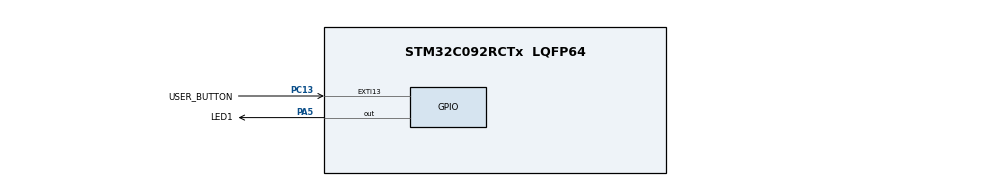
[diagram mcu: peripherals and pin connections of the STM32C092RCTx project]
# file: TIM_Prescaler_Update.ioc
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Mcu.Family=STM32C0
Mcu.Name=STM32C092RCTx
Mcu.Package=LQFP64
NVIC.EXTI4_15_IRQn=true\:0\:0\:false\:false\:true\:true\:true\:true
NVIC.TIM1_BRK_UP_TRG_COM_IRQn=true\:0\:0\:false\:false\:true\:true\:true\:true
PA5.GPIO_Label=LED1
PA5.GPIO_Speed=GPIO_SPEED_FREQ_HIGH
PA5.Signal=GPIO_Output
PC13.GPIO_Label=USER_BUTTON
PC13.GPIO_PuPd=GPIO_PULLUP
PC13.Signal=GPXTI13
ProjectManager.HeapSize=0x200
ProjectManager.StackSize=0x400
ProjectManager.TargetToolchain=EWARM V9.20
RCC.ADCFreq_Value=48000000
RCC.AHBFreq_Value=48000000
RCC.CortexFreq_Value=48000000
RCC.EXTERNAL_CLOCK_VALUE=12288000
RCC.HCLKFreq_Value=48000000
RCC.HSE_VALUE=8000000
RCC.HSISYSCLKDivider=RCC_HSI_DIV1
RCC.HSI_VALUE=48000000
RCC.LSE_VALUE=32768
RCC.SYSCLKFreq_VALUE=48000000
TIM1.Period=999
TIM1.Prescaler=aPrescaler[0]
VP_TIM1_VS_ClockSourceINT.Mode=Internal
board=custom

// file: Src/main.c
/* USER CODE BEGIN Header */
/**
  ******************************************************************************
  * @file           : main.c
  * @brief          : Main program body
  ******************************************************************************
  * @attention
  *
  * Copyright (c) 2024 STMicroelectronics.
  * All rights reserved.
  *
  * This software is licensed under terms that can be found in the LICENSE file
  * in the root directory of this software component.
  * If no LICENSE file comes with this software, it is provided AS-IS.
  *
  ******************************************************************************
  */
/* USER CODE END Header */
#include "main.h"

/* USER CODE BEGIN PD */
#define TAB_SIZE 3
/* USER CODE END PD */

/* USER CODE BEGIN PV */
/* Prescaler value table for 4kHz, 2kHz and 1kHz */
static uint32_t aPrescaler[TAB_SIZE] = {12000-1, 24000-1, 48000-1};

/* Actual autoreload value multiplication factor */
static uint32_t prescaler_index = 1;
/* USER CODE END PV */

void SystemClock_Config(void);
static void MX_GPIO_Init(void);
static void MX_TIM1_Init(void);

int main(void)
{

  /* MCU Configuration--------------------------------------------------------*/

  /* Reset of all peripherals, Initializes the Flash interface and the Systick. */
  LL_APB2_GRP1_EnableClock(LL_APB2_GRP1_PERIPH_SYSCFG);
  LL_APB1_GRP1_EnableClock(LL_APB1_GRP1_PERIPH_PWR);

  /* SysTick_IRQn interrupt configuration */
  NVIC_SetPriority(SysTick_IRQn, 3);

  /* Configure the system clock */
  SystemClock_Config();

  /* Initialize all configured peripherals */
  MX_GPIO_Init();
  MX_TIM1_Init();
  /* USER CODE BEGIN 2 */

  /* Enable Update interrupt */
  LL_TIM_EnableIT_UPDATE(TIM1);

  /* Enable counter */
  LL_TIM_EnableCounter(TIM1);

  /* USER CODE END 2 */

  /* Infinite loop */
  while (1)
  {

  }
}

void SystemClock_Config(void)
{

  LL_FLASH_SetLatency(LL_FLASH_LATENCY_1);

  /* HSI configuration and activation */
  LL_RCC_HSI_Enable();
  while(LL_RCC_HSI_IsReady() != 1)
  {
  }

  LL_RCC_HSI_SetCalibTrimming(64);
  LL_RCC_SetHSIDiv(LL_RCC_HSI_DIV_1);
  /* Set AHB prescaler*/
  LL_RCC_SetAHBPrescaler(LL_RCC_HCLK_DIV_1);

  LL_RCC_SetSYSDivider(LL_RCC_SYSCLK_DIV_1);
  /* Sysclk activation on the HSI */
  LL_RCC_SetSysClkSource(LL_RCC_SYS_CLKSOURCE_HSI);
  while(LL_RCC_GetSysClkSource() != LL_RCC_SYS_CLKSOURCE_STATUS_HSI)
  {
  }

  /* Set APB1 prescaler*/
  LL_RCC_SetAPB1Prescaler(LL_RCC_APB1_DIV_1);
  LL_Init1msTick(48000000);
  /* Update CMSIS variable (which can be updated also through SystemCoreClockUpdate function) */
  LL_SetSystemCoreClock(48000000);
}

static void MX_TIM1_Init(void)
{

  LL_TIM_InitTypeDef TIM_InitStruct = {0};

  /* Peripheral clock enable */
  LL_APB2_GRP1_EnableClock(LL_APB2_GRP1_PERIPH_TIM1);

  /* TIM1 interrupt Init */
  NVIC_SetPriority(TIM1_BRK_UP_TRG_COM_IRQn, 0);
  NVIC_EnableIRQ(TIM1_BRK_UP_TRG_COM_IRQn);

  /* USER CODE BEGIN TIM1_Init 1 */

  /* Disable update interrupt with update event generation (TIM1_EGR.UG).
     Avoid update interrupt with LL_TIM_Init where an update event is
     generated to load the values in the active registers. */
  LL_TIM_SetUpdateSource(TIM1, LL_TIM_UPDATESOURCE_COUNTER);

  /* USER CODE END TIM1_Init 1 */
  TIM_InitStruct.Prescaler = aPrescaler[0];
  TIM_InitStruct.CounterMode = LL_TIM_COUNTERMODE_UP;
  TIM_InitStruct.Autoreload = 999;
  TIM_InitStruct.ClockDivision = LL_TIM_CLOCKDIVISION_DIV1;
  TIM_InitStruct.RepetitionCounter = 0;
  LL_TIM_Init(TIM1, &TIM_InitStruct);
  LL_TIM_DisableARRPreload(TIM1);
  LL_TIM_SetClockSource(TIM1, LL_TIM_CLOCKSOURCE_INTERNAL);
  LL_TIM_SetTriggerOutput(TIM1, LL_TIM_TRGO_RESET);
  LL_TIM_SetTriggerOutput2(TIM1, LL_TIM_TRGO2_RESET);
  LL_TIM_DisableMasterSlaveMode(TIM1);

}

static void MX_GPIO_Init(void)
{
  LL_EXTI_InitTypeDef EXTI_InitStruct = {0};
  LL_GPIO_InitTypeDef GPIO_InitStruct = {0};

  /* GPIO Ports Clock Enable */
  LL_IOP_GRP1_EnableClock(LL_IOP_GRP1_PERIPH_GPIOC);
  LL_IOP_GRP1_EnableClock(LL_IOP_GRP1_PERIPH_GPIOA);

  /**/
  LL_GPIO_ResetOutputPin(LED1_GPIO_Port, LED1_Pin);

  /**/
  EXTI_InitStruct.Line_0_31 = LL_EXTI_LINE_13;
  EXTI_InitStruct.LineCommand = ENABLE;
  EXTI_InitStruct.Mode = LL_EXTI_MODE_IT;
  EXTI_InitStruct.Trigger = LL_EXTI_TRIGGER_RISING;
  LL_EXTI_Init(&EXTI_InitStruct);

  /**/
  LL_GPIO_SetPinMode(USER_BUTTON_GPIO_Port, USER_BUTTON_Pin, LL_GPIO_MODE_INPUT);

  /**/
  LL_GPIO_SetPinPull(USER_BUTTON_GPIO_Port, USER_BUTTON_Pin, LL_GPIO_PULL_UP);

  /**/
  LL_EXTI_SetEXTISource(LL_EXTI_CONFIG_PORTC, LL_EXTI_CONFIG_LINE13);

  /**/
  GPIO_InitStruct.Pin = LED1_Pin;
  GPIO_InitStruct.Mode = LL_GPIO_MODE_OUTPUT;
  GPIO_InitStruct.Speed = LL_GPIO_SPEED_FREQ_HIGH;
  GPIO_InitStruct.OutputType = LL_GPIO_OUTPUT_PUSHPULL;
  GPIO_InitStruct.Pull = LL_GPIO_PULL_NO;
  LL_GPIO_Init(LED1_GPIO_Port, &GPIO_InitStruct);

  /* EXTI interrupt init*/
  NVIC_SetPriority(EXTI4_15_IRQn, 0);
  NVIC_EnableIRQ(EXTI4_15_IRQn);

}

/* USER CODE BEGIN 4 */
/**
  * @brief  Update the timer update event period
  * @param  None
  * @retval None
  */
void UserButton_Callback(void)
{
  /* Change the update event period by modifying the prescaler value, i.e.
   * TIM counter clock (tim_cnt_ck).
   * Prescaler value is taken into account at next update event (UEV). */

  LL_TIM_SetPrescaler(TIM1, aPrescaler[prescaler_index]);

  /* Loop on prescaler table index according to table size */
  prescaler_index = prescaler_index >= (TAB_SIZE-1) ? 0 : prescaler_index+1;
}

/**
  * @brief  Timer update interrupt processing
  * @param  None
  * @retval None
  */
void TimerUpdate_Callback(void)
{
  LL_GPIO_TogglePin(LED1_GPIO_Port, LED1_Pin);
}
/* USER CODE END 4 */

void Error_Handler(void)
{
  __disable_irq();
  while (1)
  {
  }
}
